# XMC4500 register map
Vendor: Infineon; File version: 1.2.0 (Reference Manual v1.2)
CPU: CM4 r2p0, little endian, MPU, FPU, 6 interrupt priority bits
Registers are 32-bit, read-write, reset 0x0 unless marked. A register's access mark holds for its fields unless they carry their own. Offsets are from the block's base; [hi:lo] are bit positions; {n}, {i} and the like mark numbered series.

## ETH0 — Ethernet Unit 0
Base 0x5000C000
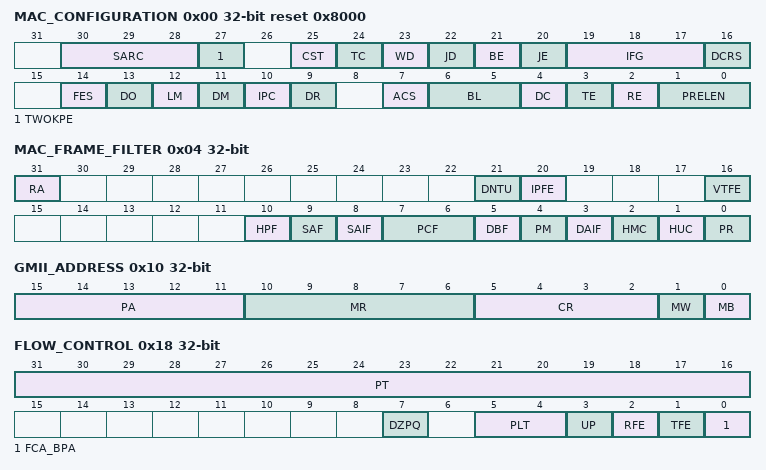
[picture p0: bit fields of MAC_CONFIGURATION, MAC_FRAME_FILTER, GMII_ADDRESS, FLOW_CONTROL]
0x00 MAC_CONFIGURATION access per field reset 0x8000
  [30:28] SARC ro — Source Address Insertion or Replacement Control
  [27] TWOKPE rw — IEEE 802.3as support for 2K packets Enable
  [25] CST rw — CRC Stripping of Type Frames
  [24] TC ro — Transmit Configuration in RMII
  [23] WD rw — Watchdog Disable
  [22] JD rw — Jabber Disable
  [21] BE ro — Frame Burst Enable
  [20] JE rw — Jumbo Frame Enable
  [19:17] IFG rw — Inter-Frame Gap
  [16] DCRS rw — Disable Carrier Sense During Transmission
  [14] FES rw — Speed
  [13] DO rw — Disable Receive Own
  [12] LM rw — Loopback Mode
  [11] DM rw — Duplex Mode
  [10] IPC rw — Checksum Offload
  [9] DR rw — Disable Retry
  [7] ACS rw — Automatic Pad or CRC Stripping
  [6:5] BL rw — Back-Off Limit
  [4] DC rw — Deferral Check
  [3] TE rw — Transmitter Enable
  [2] RE rw — Receiver Enable
  [1:0] PRELEN rw — Preamble Length for Transmit Frames
0x04 MAC_FRAME_FILTER access per field
  [31] RA rw — Receive All
  [21] DNTU ro — Drop non-TCP/UDP over IP Frames
  [20] IPFE ro — Layer 3 and Layer 4 Filter Enable
  [16] VTFE rw — VLAN Tag Filter Enable
  [10] HPF rw — Hash or Perfect Filter
  [9] SAF rw — Source Address Filter Enable
  [8] SAIF rw — SA Inverse Filtering
  [7:6] PCF rw — Pass Control Frames
  [5] DBF rw — Disable Broadcast Frames
  [4] PM rw — Pass All Multicast
  [3] DAIF rw — DA Inverse Filtering
  [2] HMC rw — Hash Multicast
  [1] HUC rw — Hash Unicast
  [0] PR rw — Promiscuous Mode
0x08 HASH_TABLE_HIGH
  [31:0] HTH — Hash Table High
0x0C HASH_TABLE_LOW
  [31:0] HTL — Hash Table Low
0x10 GMII_ADDRESS access per field — MII Address Register
  [15:11] PA rw — Physical Layer Address
  [10:6] MR rw — MII Register
  [5:2] CR rw — CSR Clock Range
  [1] MW rw — MII Write
  [0] MB rw — MII Busy
0x14 GMII_DATA access per field — MII Data Register
  [15:0] MD rw — MII Data
0x18 FLOW_CONTROL access per field
  [31:16] PT rw — Pause Time
  [7] DZPQ rw — Disable Zero-Quanta Pause
  [5:4] PLT rw — Pause Low Threshold
  [3] UP rw — Unicast Pause Frame Detect
  [2] RFE rw — Receive Flow Control Enable
  [1] TFE rw — Transmit Flow Control Enable
  [0] FCA_BPA rw — Flow Control Busy or Backpressure Activate
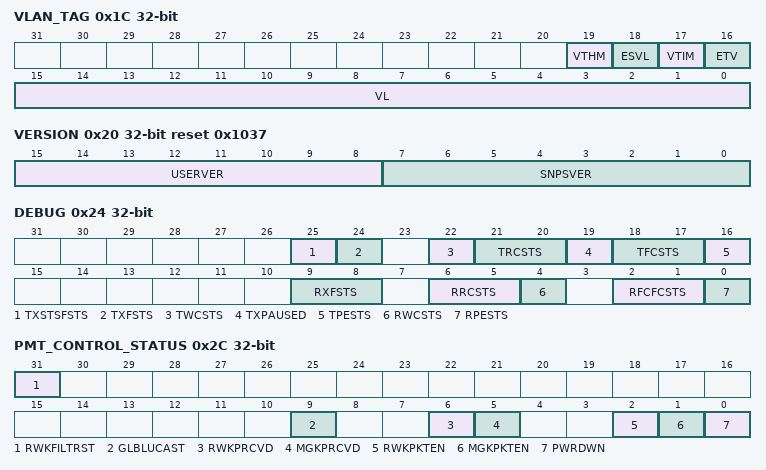
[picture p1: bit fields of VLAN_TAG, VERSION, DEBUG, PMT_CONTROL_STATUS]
0x1C VLAN_TAG access per field
  [19] VTHM ro — VLAN Tag Hash Table Match Enable
  [18] ESVL rw — Enable S-VLAN
  [17] VTIM rw — VLAN Tag Inverse Match Enable
  [16] ETV rw — Enable 12-Bit VLAN Tag Comparison
  [15:0] VL rw — VLAN Tag Identifier for Receive Frames
0x20 VERSION ro reset 0x1037
  [15:8] USERVER — User-defined Version (Configured with the coreConsultant)
  [7:0] SNPSVER — Synopsys-defined Version (3.7)
0x24 DEBUG ro
  [25] TXSTSFSTS — MTL TxStatus FIFO Full Status
  [24] TXFSTS — MTL Tx FIFO Not Empty Status
  [22] TWCSTS — MTL Tx FIFO Write Controller Active Status
  [21:20] TRCSTS — MTL Tx FIFO Read Controller Status
  [19] TXPAUSED — MAC transmitter in PAUSE
  [18:17] TFCSTS — MAC Transmit Frame Controller Status
  [16] TPESTS — MAC MII Transmit Protocol Engine Status
  [9:8] RXFSTS — MTL Rx FIFO Fill-level Status
  [6:5] RRCSTS — MTL Rx FIFO Read Controller State
  [4] RWCSTS — MTL Rx FIFO Write Controller Active Status
  [2:1] RFCFCSTS — MAC Receive Frame Controller FIFO Status
  [0] RPESTS — MAC MII Receive Protocol Engine Status
0x28 REMOTE_WAKE_UP_FRAME_FILTER
  [31:0] WKUPFRMFTR — Remote Wake-Up Frame Filter
0x2C PMT_CONTROL_STATUS access per field — PMT Control and Status Register
  [31] RWKFILTRST rw — Wake-Up Frame Filter Register Pointer Reset
  [9] GLBLUCAST rw — Global Unicast
  [6] RWKPRCVD ro — Wake-Up Frame Received
  [5] MGKPRCVD ro — Magic Packet Received
  [2] RWKPKTEN rw — Wake-Up Frame Enable
  [1] MGKPKTEN rw — Magic Packet Enable
  [0] PWRDWN rw — Power Down
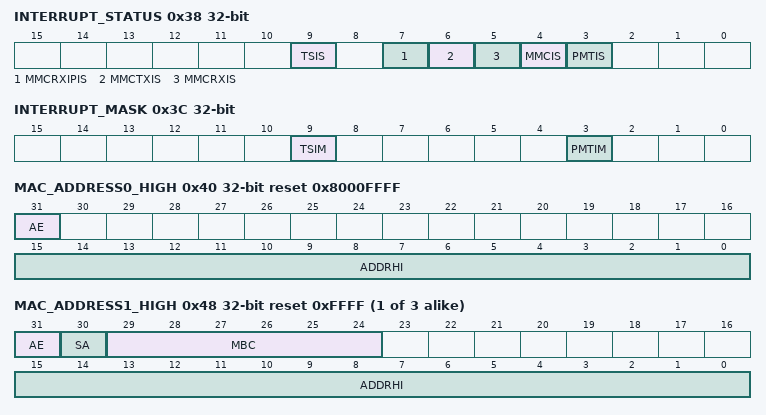
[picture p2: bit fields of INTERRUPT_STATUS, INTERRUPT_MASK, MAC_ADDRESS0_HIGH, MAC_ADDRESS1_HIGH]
0x38 INTERRUPT_STATUS ro — Interrupt Register
  [9] TSIS — Timestamp Interrupt Status
  [7] MMCRXIPIS — MMC Receive Checksum Offload Interrupt Status
  [6] MMCTXIS — MMC Transmit Interrupt Status
  [5] MMCRXIS — MMC Receive Interrupt Status
  [4] MMCIS — MMC Interrupt Status
  [3] PMTIS — PMT Interrupt Status
0x3C INTERRUPT_MASK access per field
  [9] TSIM rw — Timestamp Interrupt Mask
  [3] PMTIM rw — PMT Interrupt Mask
0x40 MAC_ADDRESS0_HIGH access per field reset 0x8000FFFF
  [31] AE ro — Address Enable
  [15:0] ADDRHI rw — MAC Address0 [47:32]
{0x44+8i} MAC_ADDRESS{i}_LOW reset 0xFFFFFFFF (i=0..3)
  [31:0] ADDRLO — MAC Address{i} [31:0]
{0x40+8i} MAC_ADDRESS{i}_HIGH access per field reset 0xFFFF (i=1..3)
  [31] AE rw — Address Enable
  [30] SA rw — Source Address
  [29:24] MBC rw — Mask Byte Control
  [15:0] ADDRHI rw — MAC Address{i} [47:32]
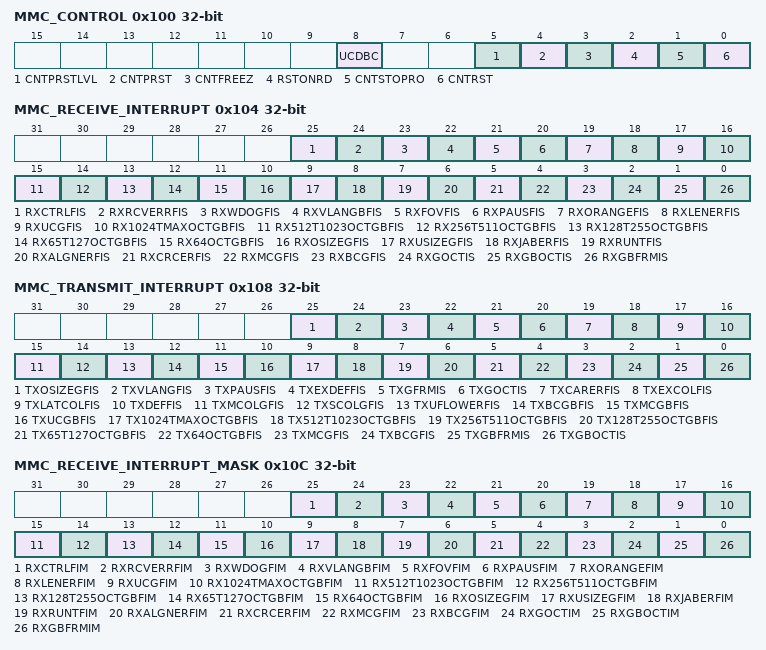
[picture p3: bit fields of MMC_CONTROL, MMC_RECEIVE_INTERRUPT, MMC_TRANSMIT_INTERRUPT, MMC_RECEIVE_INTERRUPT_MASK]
0x100 MMC_CONTROL access per field
  [8] UCDBC rw — Update MMC Counters for Dropped Broadcast Frames
  [5] CNTPRSTLVL rw — Full-Half Preset
  [4] CNTPRST rw — Counters Preset
  [3] CNTFREEZ rw — MMC Counter Freeze
  [2] RSTONRD rw — Reset on Read
  [1] CNTSTOPRO rw — Counters Stop Rollover
  [0] CNTRST rw — Counters Reset
0x104 MMC_RECEIVE_INTERRUPT ro
  [25] RXCTRLFIS — MMC Receive Control Frame Counter Interrupt Status
  [24] RXRCVERRFIS — MMC Receive Error Frame Counter Interrupt Status
  [23] RXWDOGFIS — MMC Receive Watchdog Error Frame Counter Interrupt Status
  [22] RXVLANGBFIS — MMC Receive VLAN Good Bad Frame Counter Interrupt Status
  [21] RXFOVFIS — MMC Receive FIFO Overflow Frame Counter Interrupt Status
  [20] RXPAUSFIS — MMC Receive Pause Frame Counter Interrupt Status
  [19] RXORANGEFIS — MMC Receive Out Of Range Error Frame Counter Interrupt Status
  [18] RXLENERFIS — MMC Receive Length Error Frame Counter Interrupt Status
  [17] RXUCGFIS — MMC Receive Unicast Good Frame Counter Interrupt Status
  [16] RX1024TMAXOCTGBFIS — MMC Receive 1024 to Maximum Octet Good Bad Frame Counter Interrupt Status
  [15] RX512T1023OCTGBFIS — MMC Receive 512 to 1023 Octet Good Bad Frame Counter Interrupt Status
  [14] RX256T511OCTGBFIS — MMC Receive 256 to 511 Octet Good Bad Frame Counter Interrupt Status
  [13] RX128T255OCTGBFIS — MMC Receive 128 to 255 Octet Good Bad Frame Counter Interrupt Status
  [12] RX65T127OCTGBFIS — MMC Receive 65 to 127 Octet Good Bad Frame Counter Interrupt Status
  [11] RX64OCTGBFIS — MMC Receive 64 Octet Good Bad Frame Counter Interrupt Status
  [10] RXOSIZEGFIS — MMC Receive Oversize Good Frame Counter Interrupt Status
  [9] RXUSIZEGFIS — MMC Receive Undersize Good Frame Counter Interrupt Status
  [8] RXJABERFIS — MMC Receive Jabber Error Frame Counter Interrupt Status
  [7] RXRUNTFIS — MMC Receive Runt Frame Counter Interrupt Status
  [6] RXALGNERFIS — MMC Receive Alignment Error Frame Counter Interrupt Status
  [5] RXCRCERFIS — MMC Receive CRC Error Frame Counter Interrupt Status
  [4] RXMCGFIS — MMC Receive Multicast Good Frame Counter Interrupt Status
  [3] RXBCGFIS — MMC Receive Broadcast Good Frame Counter Interrupt Status.
  [2] RXGOCTIS — MMC Receive Good Octet Counter Interrupt Status.
  [1] RXGBOCTIS — MMC Receive Good Bad Octet Counter Interrupt Status
  [0] RXGBFRMIS — MMC Receive Good Bad Frame Counter Interrupt Status
0x108 MMC_TRANSMIT_INTERRUPT ro
  [25] TXOSIZEGFIS — MMC Transmit Oversize Good Frame Counter Interrupt Status
  [24] TXVLANGFIS — MMC Transmit VLAN Good Frame Counter Interrupt Status
  [23] TXPAUSFIS — MMC Transmit Pause Frame Counter Interrupt Status
  [22] TXEXDEFFIS — MMC Transmit Excessive Deferral Frame Counter Interrupt Status
  [21] TXGFRMIS — MMC Transmit Good Frame Counter Interrupt Status
  [20] TXGOCTIS — MMC Transmit Good Octet Counter Interrupt Status
  [19] TXCARERFIS — MMC Transmit Carrier Error Frame Counter Interrupt Status
  [18] TXEXCOLFIS — MMC Transmit Excessive Collision Frame Counter Interrupt Status
  [17] TXLATCOLFIS — MMC Transmit Late Collision Frame Counter Interrupt Status
  [16] TXDEFFIS — MMC Transmit Deferred Frame Counter Interrupt Status
  [15] TXMCOLGFIS — MMC Transmit Multiple Collision Good Frame Counter Interrupt Status
  [14] TXSCOLGFIS — MMC Transmit Single Collision Good Frame Counter Interrupt Status
  [13] TXUFLOWERFIS — MMC Transmit Underflow Error Frame Counter Interrupt Status
  [12] TXBCGBFIS — MMC Transmit Broadcast Good Bad Frame Counter Interrupt Status
  [11] TXMCGBFIS — MMC Transmit Multicast Good Bad Frame Counter Interrupt Status
  [10] TXUCGBFIS — MMC Transmit Unicast Good Bad Frame Counter Interrupt Status
  [9] TX1024TMAXOCTGBFIS — MMC Transmit 1024 to Maximum Octet Good Bad Frame Counter Interrupt Status
  [8] TX512T1023OCTGBFIS — MMC Transmit 512 to 1023 Octet Good Bad Frame Counter Interrupt Status
  [7] TX256T511OCTGBFIS — MMC Transmit 256 to 511 Octet Good Bad Frame Counter Interrupt Status
  [6] TX128T255OCTGBFIS — MMC Transmit 128 to 255 Octet Good Bad Frame Counter Interrupt Status
  [5] TX65T127OCTGBFIS — MMC Transmit 65 to 127 Octet Good Bad Frame Counter Interrupt Status
  [4] TX64OCTGBFIS — MMC Transmit 64 Octet Good Bad Frame Counter Interrupt Status.
  [3] TXMCGFIS — MMC Transmit Multicast Good Frame Counter Interrupt Status
  [2] TXBCGFIS — MMC Transmit Broadcast Good Frame Counter Interrupt Status
  [1] TXGBFRMIS — MMC Transmit Good Bad Frame Counter Interrupt Status
  [0] TXGBOCTIS — MMC Transmit Good Bad Octet Counter Interrupt Status
0x10C MMC_RECEIVE_INTERRUPT_MASK access per field — MMC Reveive Interrupt Mask Register
  [25] RXCTRLFIM rw — MMC Receive Control Frame Counter Interrupt Mask
  [24] RXRCVERRFIM rw — MMC Receive Error Frame Counter Interrupt Mask
  [23] RXWDOGFIM rw — MMC Receive Watchdog Error Frame Counter Interrupt Mask
  [22] RXVLANGBFIM rw — MMC Receive VLAN Good Bad Frame Counter Interrupt Mask
  [21] RXFOVFIM rw — MMC Receive FIFO Overflow Frame Counter Interrupt Mask
  [20] RXPAUSFIM rw — MMC Receive Pause Frame Counter Interrupt Mask
  [19] RXORANGEFIM rw — MMC Receive Out Of Range Error Frame Counter Interrupt Mask
  [18] RXLENERFIM rw — MMC Receive Length Error Frame Counter Interrupt Mask
  [17] RXUCGFIM rw — MMC Receive Unicast Good Frame Counter Interrupt Mask
  [16] RX1024TMAXOCTGBFIM rw — MMC Receive 1024 to Maximum Octet Good Bad Frame Counter Interrupt Mask
  [15] RX512T1023OCTGBFIM rw — MMC Receive 512 to 1023 Octet Good Bad Frame Counter Interrupt Mask
  [14] RX256T511OCTGBFIM rw — MMC Receive 256 to 511 Octet Good Bad Frame Counter Interrupt Mask
  [13] RX128T255OCTGBFIM rw — MMC Receive 128 to 255 Octet Good Bad Frame Counter Interrupt Mask
  [12] RX65T127OCTGBFIM rw — MMC Receive 65 to 127 Octet Good Bad Frame Counter Interrupt Mask
  [11] RX64OCTGBFIM rw — MMC Receive 64 Octet Good Bad Frame Counter Interrupt Mask
  [10] RXOSIZEGFIM rw — MMC Receive Oversize Good Frame Counter Interrupt Mask
  [9] RXUSIZEGFIM rw — MMC Receive Undersize Good Frame Counter Interrupt Mask
  [8] RXJABERFIM rw — MMC Receive Jabber Error Frame Counter Interrupt Mask
  [7] RXRUNTFIM rw — MMC Receive Runt Frame Counter Interrupt Mask
  [6] RXALGNERFIM rw — MMC Receive Alignment Error Frame Counter Interrupt Mask
  [5] RXCRCERFIM rw — MMC Receive CRC Error Frame Counter Interrupt Mask
  [4] RXMCGFIM rw — MMC Receive Multicast Good Frame Counter Interrupt Mask
  [3] RXBCGFIM rw — MMC Receive Broadcast Good Frame Counter Interrupt Mask
  [2] RXGOCTIM rw — MMC Receive Good Octet Counter Interrupt Mask
  [1] RXGBOCTIM rw — MMC Receive Good Bad Octet Counter Interrupt Mask
  [0] RXGBFRMIM rw — MMC Receive Good Bad Frame Counter Interrupt Mask
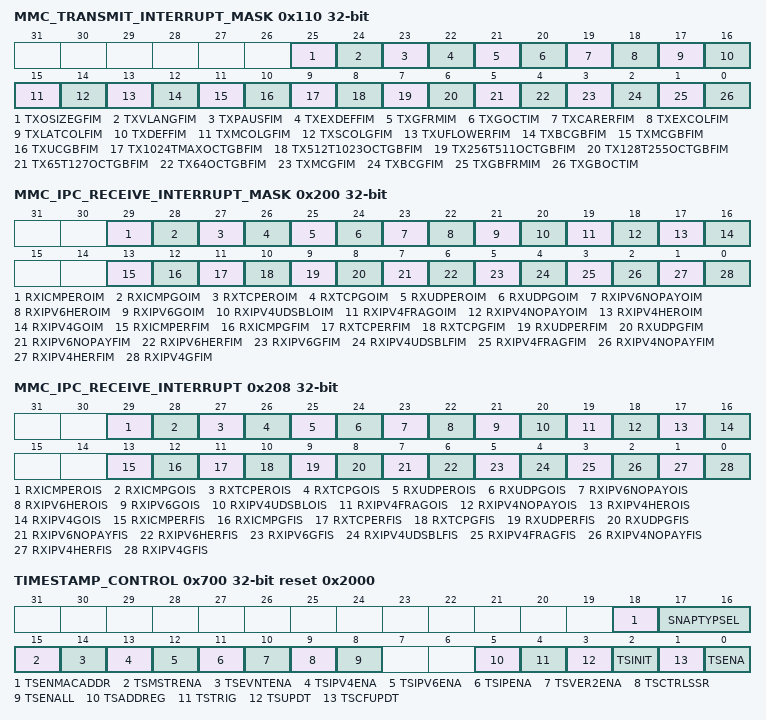
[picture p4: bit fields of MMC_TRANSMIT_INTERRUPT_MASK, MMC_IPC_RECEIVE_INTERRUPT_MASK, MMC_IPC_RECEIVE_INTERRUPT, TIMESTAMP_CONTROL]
0x110 MMC_TRANSMIT_INTERRUPT_MASK access per field
  [25] TXOSIZEGFIM rw — MMC Transmit Oversize Good Frame Counter Interrupt Mask
  [24] TXVLANGFIM rw — MMC Transmit VLAN Good Frame Counter Interrupt Mask
  [23] TXPAUSFIM rw — MMC Transmit Pause Frame Counter Interrupt Mask
  [22] TXEXDEFFIM rw — MMC Transmit Excessive Deferral Frame Counter Interrupt Mask
  [21] TXGFRMIM rw — MMC Transmit Good Frame Counter Interrupt Mask
  [20] TXGOCTIM rw — MMC Transmit Good Octet Counter Interrupt Mask
  [19] TXCARERFIM rw — MMC Transmit Carrier Error Frame Counter Interrupt Mask
  [18] TXEXCOLFIM rw — MMC Transmit Excessive Collision Frame Counter Interrupt Mask
  [17] TXLATCOLFIM rw — MMC Transmit Late Collision Frame Counter Interrupt Mask
  [16] TXDEFFIM rw — MMC Transmit Deferred Frame Counter Interrupt Mask
  [15] TXMCOLGFIM rw — MMC Transmit Multiple Collision Good Frame Counter Interrupt Mask
  [14] TXSCOLGFIM rw — MMC Transmit Single Collision Good Frame Counter Interrupt Mask
  [13] TXUFLOWERFIM rw — MMC Transmit Underflow Error Frame Counter Interrupt Mask
  [12] TXBCGBFIM rw — MMC Transmit Broadcast Good Bad Frame Counter Interrupt Mask
  [11] TXMCGBFIM rw — MMC Transmit Multicast Good Bad Frame Counter Interrupt Mask
  [10] TXUCGBFIM rw — MMC Transmit Unicast Good Bad Frame Counter Interrupt Mask
  [9] TX1024TMAXOCTGBFIM rw — MMC Transmit 1024 to Maximum Octet Good Bad Frame Counter Interrupt Mask
  [8] TX512T1023OCTGBFIM rw — MMC Transmit 512 to 1023 Octet Good Bad Frame Counter Interrupt Mask
  [7] TX256T511OCTGBFIM rw — MMC Transmit 256 to 511 Octet Good Bad Frame Counter Interrupt Mask
  [6] TX128T255OCTGBFIM rw — MMC Transmit 128 to 255 Octet Good Bad Frame Counter Interrupt Mask
  [5] TX65T127OCTGBFIM rw — MMC Transmit 65 to 127 Octet Good Bad Frame Counter Interrupt Mask
  [4] TX64OCTGBFIM rw — MMC Transmit 64 Octet Good Bad Frame Counter Interrupt Mask
  [3] TXMCGFIM rw — MMC Transmit Multicast Good Frame Counter Interrupt Mask
  [2] TXBCGFIM rw — MMC Transmit Broadcast Good Frame Counter Interrupt Mask
  [1] TXGBFRMIM rw — MMC Transmit Good Bad Frame Counter Interrupt Mask
  [0] TXGBOCTIM rw — MMC Transmit Good Bad Octet Counter Interrupt Mask
0x114 TX_OCTET_COUNT_GOOD_BAD ro — Transmit Octet Count for Good and Bad Frames Register
  [31:0] TXOCTGB — This field indicates the number of bytes transmitted in good and bad frames exclusive of preamble and retried bytes.
0x118 TX_FRAME_COUNT_GOOD_BAD ro — Transmit Frame Count for Goodand Bad Frames Register
  [31:0] TXFRMGB — This field indicates the number of good and bad frames transmitted, exclusive of retried frames
0x11C TX_BROADCAST_FRAMES_GOOD ro — Transmit Frame Count for Good Broadcast Frames
  [31:0] TXBCASTG — This field indicates the number of transmitted good broadcast frames.
0x120 TX_MULTICAST_FRAMES_GOOD ro — Transmit Frame Count for Good Multicast Frames
  [31:0] TXMCASTG — This field indicates the number of transmitted good multicast frames.
0x124 TX_64OCTETS_FRAMES_GOOD_BAD ro — Transmit Octet Count for Good and Bad 64 Byte Frames
  [31:0] TX64OCTGB — This field indicates the number of transmitted good and bad frames with length of 64 bytes, exclusive of preamble and retried frames.
0x128 TX_65TO127OCTETS_FRAMES_GOOD_BAD ro — Transmit Octet Count for Good and Bad 65 to 127 Bytes Frames
  [31:0] TX65_127OCTGB — This field indicates the number of transmitted good and bad frames with length between 65 and 127 (inclusive) bytes, exclusive of preamble and retried frames.
0x12C TX_128TO255OCTETS_FRAMES_GOOD_BAD ro — Transmit Octet Count for Good and Bad 128 to 255 Bytes Frames
  [31:0] TX128_255OCTGB — This field indicates the number of transmitted good and bad frames with length between 128 and 255 (inclusive) bytes, exclusive of preamble and retried frames.
0x130 TX_256TO511OCTETS_FRAMES_GOOD_BAD ro — Transmit Octet Count for Good and Bad 256 to 511 Bytes Frames
  [31:0] TX256_511OCTGB — This field indicates the number of transmitted good and bad frames with length between 256 and 511 (inclusive) bytes, exclusive of preamble and retried frames.
0x134 TX_512TO1023OCTETS_FRAMES_GOOD_BAD ro — Transmit Octet Count for Good and Bad 512 to 1023 Bytes Frames
  [31:0] TX512_1023OCTGB — This field indicates the number of transmitted good and bad frames with length between 512 and 1,023 (inclusive) bytes, exclusive of preamble and retried frames.
0x138 TX_1024TOMAXOCTETS_FRAMES_GOOD_BAD ro — Transmit Octet Count for Good and Bad 1024 to Maxsize Bytes Frames
  [31:0] TX1024_MAXOCTGB — This field indicates the number of good and bad frames transmitted with length between 1,024 and maxsize (inclusive) bytes, exclusive of preamble and retried frames.
0x13C TX_UNICAST_FRAMES_GOOD_BAD ro — Transmit Frame Count for Good and Bad Unicast Frames
  [31:0] TXUCASTGB — This field indicates the number of transmitted good and bad unicast frames.
0x140 TX_MULTICAST_FRAMES_GOOD_BAD ro — Transmit Frame Count for Good and Bad Multicast Frames
  [31:0] TXMCASTGB — This field indicates the number of transmitted good and bad multicast frames.
0x144 TX_BROADCAST_FRAMES_GOOD_BAD ro — Transmit Frame Count for Good and Bad Broadcast Frames
  [31:0] TXBCASTGB — This field indicates the number of transmitted good and bad broadcast frames.
0x148 TX_UNDERFLOW_ERROR_FRAMES ro — Transmit Frame Count for Underflow Error Frames
  [31:0] TXUNDRFLW — This field indicates the number of frames aborted because of frame underflow error.
0x14C TX_SINGLE_COLLISION_GOOD_FRAMES ro — Transmit Frame Count for Frames Transmitted after Single Collision
  [31:0] TXSNGLCOLG — This field indicates the number of successfully transmitted frames after a single collision in the half-duplex mode.
0x150 TX_MULTIPLE_COLLISION_GOOD_FRAMES ro — Transmit Frame Count for Frames Transmitted after Multiple Collision
  [31:0] TXMULTCOLG — This field indicates the number of successfully transmitted frames after multiple collisions in the half-duplex mode.
0x154 TX_DEFERRED_FRAMES ro
  [31:0] TXDEFRD — This field indicates the number of successfully transmitted frames after a deferral in the half-duplex mode.
0x158 TX_LATE_COLLISION_FRAMES ro — Transmit Frame Count for Late Collision Error Frames
  [31:0] TXLATECOL — This field indicates the number of frames aborted because of late collision error.
0x15C TX_EXCESSIVE_COLLISION_FRAMES ro — Transmit Frame Count for Excessive Collision Error Frames
  [31:0] TXEXSCOL — This field indicates the number of frames aborted because of excessive (16) collision error.
0x160 TX_CARRIER_ERROR_FRAMES ro — Transmit Frame Count for Carrier Sense Error Frames
  [31:0] TXCARR — This field indicates the number of frames aborted because of carrier sense error (no carrier or loss of carrier).
0x164 TX_OCTET_COUNT_GOOD ro
  [31:0] TXOCTG — This field indicates the number of bytes transmitted, exclusive of preamble, in good frames.
0x168 TX_FRAME_COUNT_GOOD ro
  [31:0] TXFRMG — This field indicates the number of transmitted good frames, exclusive of preamble.
0x16C TX_EXCESSIVE_DEFERRAL_ERROR ro — Transmit Frame Count for Excessive Deferral Error Frames
  [31:0] TXEXSDEF — This field indicates the number of frames aborted because of excessive deferral error, that is, frames deferred for more than two max-sized frame times.
0x170 TX_PAUSE_FRAMES ro — Transmit Frame Count for Good PAUSE Frames
  [31:0] TXPAUSE — This field indicates the number of transmitted good PAUSE frames.
0x174 TX_VLAN_FRAMES_GOOD ro — Transmit Frame Count for Good VLAN Frames
  [31:0] TXVLANG — This register maintains the number of transmitted good VLAN frames, exclusive of retried frames.
0x178 TX_OSIZE_FRAMES_GOOD ro — Transmit Frame Count for Good Oversize Frames
  [31:0] TXOSIZG — This field indicates the number of frames transmitted without errors and with length greater than the maxsize (1,518 or 1,522 bytes for VLAN tagged frames; 2000 bytes if enabled by setting MAC Configuration.2KPE).
0x180 RX_FRAMES_COUNT_GOOD_BAD ro — Receive Frame Count for Good and Bad Frames
  [31:0] RXFRMGB — This field indicates the number of received good and bad frames.
0x184 RX_OCTET_COUNT_GOOD_BAD ro — Receive Octet Count for Good and Bad Frames
  [31:0] RXOCTGB — This field indicates the number of bytes received, exclusive of preamble, in good and bad frames.
0x188 RX_OCTET_COUNT_GOOD ro
  [31:0] RXOCTG — This field indicates the number of bytes received, exclusive of preamble, only in good frames.
0x18C RX_BROADCAST_FRAMES_GOOD ro — Receive Frame Count for Good Broadcast Frames
  [31:0] RXBCASTG — This field indicates the number of received good broadcast frames.
0x190 RX_MULTICAST_FRAMES_GOOD ro — Receive Frame Count for Good Multicast Frames
  [31:0] RXMCASTG — This field indicates the number of received good multicast frames.
0x194 RX_CRC_ERROR_FRAMES ro — Receive Frame Count for CRC Error Frames
  [31:0] RXCRCERR — This field indicates the number of frames received with CRC error.
0x198 RX_ALIGNMENT_ERROR_FRAMES ro — Receive Frame Count for Alignment Error Frames
  [31:0] RXALGNERR — This field indicates the number of frames received with alignment (dribble) error.
0x19C RX_RUNT_ERROR_FRAMES ro — Receive Frame Count for Runt Error Frames
  [31:0] RXRUNTERR — This field indicates the number of frames received with runt error(<64 bytes and CRC error).
0x1A0 RX_JABBER_ERROR_FRAMES ro — Receive Frame Count for Jabber Error Frames
  [31:0] RXJABERR — This field indicates the number of giant frames received with length (including CRC) greater than 1,518 bytes (1,522 bytes for VLAN tagged) and with CRC error. If Jumbo Frame mode is enabled, then frames of length greater than 9,018 bytes (9,022 for VLAN tagged) are considered as giant frames.
0x1A4 RX_UNDERSIZE_FRAMES_GOOD ro — Receive Frame Count for Undersize Frames
  [31:0] RXUNDERSZG — This field indicates the number of frames received with length less than 64 bytes and without errors.
0x1A8 RX_OVERSIZE_FRAMES_GOOD ro
  [31:0] RXOVERSZG — This field indicates the number of frames received without errors, with length greater than the maxsize (1,518 or 1,522 for VLAN tagged frames; 2,000 bytes if enabled by setting MAC Configuration.2KPE).
0x1AC RX_64OCTETS_FRAMES_GOOD_BAD ro — Receive Frame Count for Good and Bad 64 Byte Frames
  [31:0] RX64OCTGB — This field indicates the number of received good and bad frames with length 64 bytes, exclusive of preamble.
0x1B0 RX_65TO127OCTETS_FRAMES_GOOD_BAD ro — Receive Frame Count for Good and Bad 65 to 127 Bytes Frames
  [31:0] RX65_127OCTGB — This field indicates the number of received good and bad frames received with length between 65 and 127 (inclusive) bytes, exclusive of preamble.
0x1B4 RX_128TO255OCTETS_FRAMES_GOOD_BAD ro — Receive Frame Count for Good and Bad 128 to 255 Bytes Frames
  [31:0] RX128_255OCTGB — This field indicates the number of received good and bad frames with length between 128 and 255 (inclusive) bytes, exclusive of preamble.
0x1B8 RX_256TO511OCTETS_FRAMES_GOOD_BAD ro — Receive Frame Count for Good and Bad 256 to 511 Bytes Frames
  [31:0] RX256_511OCTGB — This field indicates the number of received good and bad frames with length between 256 and 511 (inclusive) bytes, exclusive of preamble.
0x1BC RX_512TO1023OCTETS_FRAMES_GOOD_BAD ro — Receive Frame Count for Good and Bad 512 to 1,023 Bytes Frames
  [31:0] RX512_1023OCTGB — This field indicates the number of received good and bad frames with length between 512 and 1,023 (inclusive) bytes, exclusive of preamble.
0x1C0 RX_1024TOMAXOCTETS_FRAMES_GOOD_BAD ro — Receive Frame Count for Good and Bad 1,024 to Maxsize Bytes Frames
  [31:0] RX1024_MAXOCTGB — This field indicates the number of received good and bad frames with length between 1,024 and maxsize (inclusive) bytes, exclusive of preamble and retried frames.
0x1C4 RX_UNICAST_FRAMES_GOOD ro — Receive Frame Count for Good Unicast Frames
  [31:0] RXUCASTG — This field indicates the number of received good unicast frames.
0x1C8 RX_LENGTH_ERROR_FRAMES ro — Receive Frame Count for Length Error Frames
  [31:0] RXLENERR — This field indicates the number of frames received with length error (Length type field not equal to frame size) for all frames with valid length field.
0x1CC RX_OUT_OF_RANGE_TYPE_FRAMES ro — Receive Frame Count for Out of Range Frames
  [31:0] RXOUTOFRNG — This field indicates the number of received frames with length field not equal to the valid frame size (greater than 1,500 but less than 1,536).
0x1D0 RX_PAUSE_FRAMES ro — Receive Frame Count for PAUSE Frames
  [31:0] RXPAUSEFRM — This field indicates the number of received good and valid PAUSE frames.
0x1D4 RX_FIFO_OVERFLOW_FRAMES ro — Receive Frame Count for FIFO Overflow Frames
  [31:0] RXFIFOOVFL — This field indicates the number of received frames missed because of FIFO overflow.
0x1D8 RX_VLAN_FRAMES_GOOD_BAD ro — Receive Frame Count for Good and Bad VLAN Frames
  [31:0] RXVLANFRGB — This field indicates the number of received good and bad VLAN frames.
0x1DC RX_WATCHDOG_ERROR_FRAMES ro — Receive Frame Count for Watchdog Error Frames
  [31:0] RXWDGERR — This field indicates the number of frames received with error because of the watchdog timeout error (frames with more than 2,048 bytes data load).
0x1E0 RX_RECEIVE_ERROR_FRAMES ro — Receive Frame Count for Receive Error Frames
  [31:0] RXRCVERR — This field indicates the number of frames received with error because of the watchdog timeout error (frames with more than 2,048 bytes data load).
0x1E4 RX_CONTROL_FRAMES_GOOD ro — Receive Frame Count for Good Control Frames Frames
  [31:0] RXCTRLG — This field indicates the number of frames received with error because of the watchdog timeout error (frames with more than 2,048 bytes data load).
0x200 MMC_IPC_RECEIVE_INTERRUPT_MASK access per field — MMC Receive Checksum Offload Interrupt Mask Register
  [29] RXICMPEROIM rw — MMC Receive ICMP Error Octet Counter Interrupt Mask
  [28] RXICMPGOIM rw — MMC Receive ICMP Good Octet Counter Interrupt Mask
  [27] RXTCPEROIM rw — MMC Receive TCP Error Octet Counter Interrupt Mask
  [26] RXTCPGOIM rw — MMC Receive TCP Good Octet Counter Interrupt Mask
  [25] RXUDPEROIM rw — MMC Receive UDP Error Octet Counter Interrupt Mask
  [24] RXUDPGOIM rw — MMC Receive UDP Good Octet Counter Interrupt Mask
  [23] RXIPV6NOPAYOIM rw — MMC Receive IPV6 No Payload Octet Counter Interrupt Mask
  [22] RXIPV6HEROIM rw — MMC Receive IPV6 Header Error Octet Counter Interrupt Mask
  [21] RXIPV6GOIM rw — MMC Receive IPV6 Good Octet Counter Interrupt Mask
  [20] RXIPV4UDSBLOIM rw — MMC Receive IPV4 UDP Checksum Disabled Octet Counter Interrupt Mask
  [19] RXIPV4FRAGOIM rw — MMC Receive IPV4 Fragmented Octet Counter Interrupt Mask
  [18] RXIPV4NOPAYOIM rw — MMC Receive IPV4 No Payload Octet Counter Interrupt Mask
  [17] RXIPV4HEROIM rw — MMC Receive IPV4 Header Error Octet Counter Interrupt Mask
  [16] RXIPV4GOIM rw — MMC Receive IPV4 Good Octet Counter Interrupt Mask
  [13] RXICMPERFIM rw — MMC Receive ICMP Error Frame Counter Interrupt Mask
  [12] RXICMPGFIM rw — MMC Receive ICMP Good Frame Counter Interrupt Mask
  [11] RXTCPERFIM rw — MMC Receive TCP Error Frame Counter Interrupt Mask
  [10] RXTCPGFIM rw — MMC Receive TCP Good Frame Counter Interrupt Mask
  [9] RXUDPERFIM rw — MMC Receive UDP Error Frame Counter Interrupt Mask
  [8] RXUDPGFIM rw — MMC Receive UDP Good Frame Counter Interrupt Mask
  [7] RXIPV6NOPAYFIM rw — MMC Receive IPV6 No Payload Frame Counter Interrupt Mask
  [6] RXIPV6HERFIM rw — MMC Receive IPV6 Header Error Frame Counter Interrupt Mask
  [5] RXIPV6GFIM rw — MMC Receive IPV6 Good Frame Counter Interrupt Mask
  [4] RXIPV4UDSBLFIM rw — MMC Receive IPV4 UDP Checksum Disabled Frame Counter Interrupt Mask
  [3] RXIPV4FRAGFIM rw — MMC Receive IPV4 Fragmented Frame Counter Interrupt Mask
  [2] RXIPV4NOPAYFIM rw — MMC Receive IPV4 No Payload Frame Counter Interrupt Mask
  [1] RXIPV4HERFIM rw — MMC Receive IPV4 Header Error Frame Counter Interrupt Mask
  [0] RXIPV4GFIM rw — MMC Receive IPV4 Good Frame Counter Interrupt Mask
0x208 MMC_IPC_RECEIVE_INTERRUPT ro — MMC Receive Checksum Offload Interrupt Register
  [29] RXICMPEROIS — MMC Receive ICMP Error Octet Counter Interrupt Status
  [28] RXICMPGOIS — MMC Receive ICMP Good Octet Counter Interrupt Status
  [27] RXTCPEROIS — MMC Receive TCP Error Octet Counter Interrupt Status
  [26] RXTCPGOIS — MMC Receive TCP Good Octet Counter Interrupt Status
  [25] RXUDPEROIS — MMC Receive UDP Error Octet Counter Interrupt Status
  [24] RXUDPGOIS — MMC Receive UDP Good Octet Counter Interrupt Status
  [23] RXIPV6NOPAYOIS — MMC Receive IPV6 No Payload Octet Counter Interrupt Status
  [22] RXIPV6HEROIS — MMC Receive IPV6 Header Error Octet Counter Interrupt Status
  [21] RXIPV6GOIS — MMC Receive IPV6 Good Octet Counter Interrupt Status
  [20] RXIPV4UDSBLOIS — MMC Receive IPV4 UDP Checksum Disabled Octet Counter Interrupt Status
  [19] RXIPV4FRAGOIS — MMC Receive IPV4 Fragmented Octet Counter Interrupt Status
  [18] RXIPV4NOPAYOIS — MMC Receive IPV4 No Payload Octet Counter Interrupt Status
  [17] RXIPV4HEROIS — MMC Receive IPV4 Header Error Octet Counter Interrupt Status
  [16] RXIPV4GOIS — MMC Receive IPV4 Good Octet Counter Interrupt Status
  [13] RXICMPERFIS — MMC Receive ICMP Error Frame Counter Interrupt Status
  [12] RXICMPGFIS — MMC Receive ICMP Good Frame Counter Interrupt Status
  [11] RXTCPERFIS — MMC Receive TCP Error Frame Counter Interrupt Status
  [10] RXTCPGFIS — MMC Receive TCP Good Frame Counter Interrupt Status
  [9] RXUDPERFIS — MMC Receive UDP Error Frame Counter Interrupt Status
  [8] RXUDPGFIS — MMC Receive UDP Good Frame Counter Interrupt Status
  [7] RXIPV6NOPAYFIS — MMC Receive IPV6 No Payload Frame Counter Interrupt Status
  [6] RXIPV6HERFIS — MMC Receive IPV6 Header Error Frame Counter Interrupt Status
  [5] RXIPV6GFIS — MMC Receive IPV6 Good Frame Counter Interrupt Status
  [4] RXIPV4UDSBLFIS — MMC Receive IPV4 UDP Checksum Disabled Frame Counter Interrupt Status
  [3] RXIPV4FRAGFIS — MMC Receive IPV4 Fragmented Frame Counter Interrupt Status
  [2] RXIPV4NOPAYFIS — MMC Receive IPV4 No Payload Frame Counter Interrupt Status
  [1] RXIPV4HERFIS — MMC Receive IPV4 Header Error Frame Counter Interrupt Status
  [0] RXIPV4GFIS — MMC Receive IPV4 Good Frame Counter Interrupt Status
0x210 RXIPV4_GOOD_FRAMES ro
  [31:0] RXIPV4GDFRM — This field indicates the number of good IPv4 datagrams received with the TCP, UDP, or ICMP payload.
0x214 RXIPV4_HEADER_ERROR_FRAMES ro — Receive IPV4 Header Error Frame Counter Register
  [31:0] RXIPV4HDRERRFRM — This field indicates the number of IPv4 datagrams received with header errors (checksum, length, or version mismatch).
0x218 RXIPV4_NO_PAYLOAD_FRAMES ro — Receive IPV4 No Payload Frame Counter Register
  [31:0] RXIPV4NOPAYFRM — This field indicates the number of IPv4 datagram frames received that did not have a TCP, UDP, or ICMP payload processed by the Checksum engine.
0x21C RXIPV4_FRAGMENTED_FRAMES ro — Receive IPV4 Fragmented Frame Counter Register
  [31:0] RXIPV4FRAGFRM — This field indicates the number of good IPv4 datagrams received with fragmentation.
0x220 RXIPV4_UDP_CHECKSUM_DISABLED_FRAMES ro — Receive IPV4 UDP Checksum Disabled Frame Counter Register
  [31:0] RXIPV4UDSBLFRM — This field indicates the number of received good IPv4 datagrams which have the UDP payload with checksum disabled.
0x224 RXIPV6_GOOD_FRAMES ro
  [31:0] RXIPV6GDFRM — This field indicates the number of good IPv6 datagrams received with TCP, UDP, or ICMP payloads.
0x228 RXIPV6_HEADER_ERROR_FRAMES ro — Receive IPV6 Header Error Frame Counter Register
  [31:0] RXIPV6HDRERRFRM — This field indicates the number of IPv6 datagrams received with header errors (length or version mismatch).
0x22C RXIPV6_NO_PAYLOAD_FRAMES ro — Receive IPV6 No Payload Frame Counter Register
  [31:0] RXIPV6NOPAYFRM — This field indicates the number of IPv6 datagram frames received that did not have a TCP, UDP, or ICMP payload. This includes all IPv6 datagrams with fragmentation or security extension headers.
0x230 RXUDP_GOOD_FRAMES ro
  [31:0] RXUDPGDFRM — This field indicates the number of good IP datagrams with a good UDP payload. This counter is not updated when the counter is incremented.
0x234 RXUDP_ERROR_FRAMES ro
  [31:0] RXUDPERRFRM — This field indicates the number of good IP datagrams whose UDP payload has a checksum error.
0x238 RXTCP_GOOD_FRAMES ro
  [31:0] RXTCPGDFRM — This field indicates the number of good IP datagrams with a good TCP payload.
0x23C RXTCP_ERROR_FRAMES ro
  [31:0] RXTCPERRFRM — This field indicates the number of good IP datagrams whose TCP payload has a checksum error.
0x240 RXICMP_GOOD_FRAMES ro
  [31:0] RXICMPGDFRM — This field indicates the number of good IP datagrams with a good ICMP payload.
0x244 RXICMP_ERROR_FRAMES ro
  [31:0] RXICMPERRFRM — This field indicates the number of good IP datagrams whose ICMP payload has a checksum error.
0x250 RXIPV4_GOOD_OCTETS ro
  [31:0] RXIPV4GDOCT — This field indicates the number of bytes received in good IPv4 datagrams encapsulating TCP, UDP, or ICMP data. The Ethernet header, FCS, pad, or IP pad
0x254 RXIPV4_HEADER_ERROR_OCTETS ro — Receive IPV4 Header Error Octet Counter Register
  [31:0] RXIPV4HDRERROCT — This field indicates the number of bytes received in the IPv4 datagrams with header errors (checksum, length, or version mismatch). The value in the Length field of IPv4 header is used to update this counter.
0x258 RXIPV4_NO_PAYLOAD_OCTETS ro — Receive IPV4 No Payload Octet Counter Register
  [31:0] RXIPV4NOPAYOCT — This field indicates the number of bytes received in IPv4 datagrams that did not have a TCP, UDP, or ICMP payload. The value in the IPv4 headers Length field is used to update this counter.
0x25C RXIPV4_FRAGMENTED_OCTETS ro — Receive IPV4 Fragmented Octet Counter Register
  [31:0] RXIPV4FRAGOCT — This field indicates the number of bytes received in fragmented IPv4 datagrams. The value in the IPv4 headers Length field is used to update this counter.
0x260 RXIPV4_UDP_CHECKSUM_DISABLE_OCTETS ro — Receive IPV4 Fragmented Octet Counter Register
  [31:0] RXIPV4UDSBLOCT — This field indicates the number of bytes received in a UDP segment that had the UDP checksum disabled. This counter does not count the IP Header bytes. The Ethernet header, FCS, pad, or IP pad bytes are not included in this counter.
0x264 RXIPV6_GOOD_OCTETS ro
  [31:0] RXIPV6GDOCT — Thsi field indicates the number of bytes received in good IPv6 datagrams encapsulating TCP, UDP or ICMPv6 data.
0x268 RXIPV6_HEADER_ERROR_OCTETS ro — Receive IPV6 Header Error Octet Counter Register
  [31:0] RXIPV6HDRERROCT — This field indicates the number of bytes received in IPv6 datagrams with header errors (length or version mismatch). The value in the IPv6 headers Length field is used to update this counter.
0x26C RXIPV6_NO_PAYLOAD_OCTETS ro — Receive IPV6 No Payload Octet Counter Register
  [31:0] RXIPV6NOPAYOCT — This field indicates the number of bytes received in IPv6 datagrams that did not have a TCP, UDP, or ICMP payload. The value in the IPv6 headers Length field is used to update this counter.
0x270 RXUDP_GOOD_OCTETS ro — Receive UDP Good Octets Register
  [31:0] RXUDPGDOCT — This field indicates the number of bytes received in a good UDP segment. This counter does not count IP header bytes. The Ethernet header, FCS, pad, or IP pad bytes are not included in this counter.
0x274 RXUDP_ERROR_OCTETS ro — Receive UDP Error Octets Register
  [31:0] RXUDPERROCT — This field indicates the number of bytes received in a UDP segment with checksum errors. This counter does not count the IP Header bytes. The Ethernet header, FCS, pad, or IP pad bytes are not included in this counter.
0x278 RXTCP_GOOD_OCTETS ro — Receive TCP Good Octets Register
  [31:0] RXTCPGDOCT — This field indicates the number of bytes received in a good TCP segment. This counter does not count the IP Header bytes. The Ethernet header, FCS, pad, or IP pad bytes are not included in this counter.
0x27C RXTCP_ERROR_OCTETS ro — Receive TCP Error Octets Register
  [31:0] RXTCPERROCT — Thsi field indicates the number of bytes received in a TCP segment with checksum errors. This counter does not count the IP Header bytes. The Ethernet header, FCS, pad, or IP pad bytes are not included in this counter.
0x280 RXICMP_GOOD_OCTETS ro — Receive ICMP Good Octets Register
  [31:0] RXICMPGDOCT — This field indicates the number of bytes received in a good ICMP segment. This counter does not count the IP Header bytes. The Ethernet header, FCS, pad, or IP pad bytes are not included in this counter.
0x284 RXICMP_ERROR_OCTETS ro — Receive ICMP Error Octets Register
  [31:0] RXICMPERROCT — Number of bytes received in an ICMP segment with checksum errors
0x700 TIMESTAMP_CONTROL access per field reset 0x2000
  [18] TSENMACADDR rw — Enable MAC address for PTP Frame Filtering
  [17:16] SNAPTYPSEL rw — Select PTP packets for Taking Snapshots
  [15] TSMSTRENA rw — Enable Snapshot for Messages Relevant to Master
  [14] TSEVNTENA rw — Enable Timestamp Snapshot for Event Messages
  [13] TSIPV4ENA rw — Enable Processing of PTP Frames Sent over IPv4-UDP
  [12] TSIPV6ENA rw — Enable Processing of PTP Frames Sent Over IPv6-UDP
  [11] TSIPENA rw — Enable Processing of PTP over Ethernet Frames
  [10] TSVER2ENA rw — Enable PTP packet Processing for Version 2 Format
  [9] TSCTRLSSR rw — Timestamp Digital or Binary Rollover Control
  [8] TSENALL rw — Enable Timestamp for All Frames
  [5] TSADDREG rw — Addend Reg Update
  [4] TSTRIG rw — Timestamp Interrupt Trigger Enable
  [3] TSUPDT rw — Timestamp Update
  [2] TSINIT rw — Timestamp Initialize
  [1] TSCFUPDT rw — Timestamp Fine or Coarse Update
  [0] TSENA rw — Timestamp Enable
0x704 SUB_SECOND_INCREMENT access per field
  [7:0] SSINC rw — Sub-second Increment Value
0x708 SYSTEM_TIME_SECONDS ro
  [31:0] TSS — Timestamp Second
0x70C SYSTEM_TIME_NANOSECONDS ro
  [30:0] TSSS — Timestamp Sub Seconds
0x710 SYSTEM_TIME_SECONDS_UPDATE
  [31:0] TSS — Timestamp Second
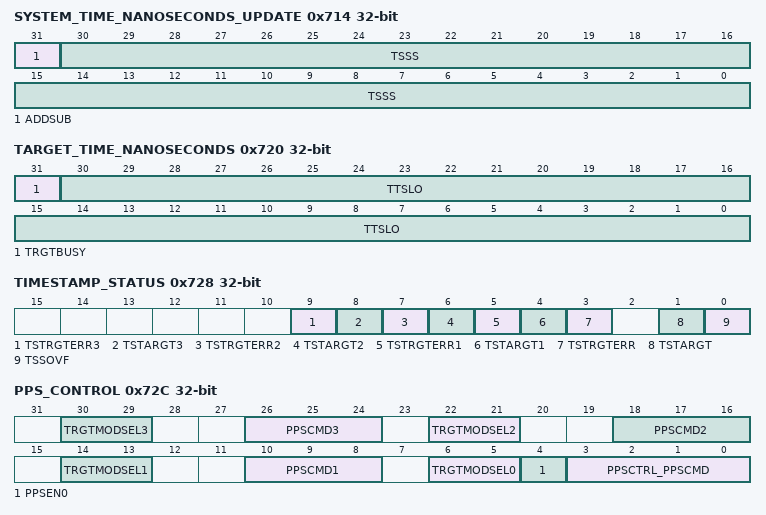
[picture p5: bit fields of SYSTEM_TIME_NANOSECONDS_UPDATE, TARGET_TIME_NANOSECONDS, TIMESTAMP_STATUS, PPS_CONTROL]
0x714 SYSTEM_TIME_NANOSECONDS_UPDATE
  [31] ADDSUB — Add or subtract time
  [30:0] TSSS — Timestamp Sub Second
0x718 TIMESTAMP_ADDEND
  [31:0] TSAR
0x71C TARGET_TIME_SECONDS
  [31:0] TSTR
0x720 TARGET_TIME_NANOSECONDS access per field
  [31] TRGTBUSY ro — Target Time Register Busy
  [30:0] TTSLO rw — Target Timestamp Low Register
0x724 SYSTEM_TIME_HIGHER_WORD_SECONDS access per field
  [15:0] TSHWR rw — Timestamp Higher Word Register
0x728 TIMESTAMP_STATUS ro
  [9] TSTRGTERR3 — Timestamp Target Time Error
  [8] TSTARGT3 — Timestamp Target Time Reached for Target Time PPS3
  [7] TSTRGTERR2 — Timestamp Target Time Error
  [6] TSTARGT2 — Timestamp Target Time Reached for Target Time PPS2
  [5] TSTRGTERR1 — Timestamp Target Time Error
  [4] TSTARGT1 — Timestamp Target Time Reached for Target Time PPS1
  [3] TSTRGTERR — Timestamp Target Time Error
  [1] TSTARGT — Timestamp Target Time Reached
  [0] TSSOVF — Timestamp Seconds Overflow
0x72C PPS_CONTROL access per field
  [8n+6:8n+5] TRGTMODSEL{n} ro (n=0..3) — Target Time Register Mode for PPS{n} Output
  [26:24] PPSCMD3 ro — Flexible PPS3 Output Control
  [18:16] PPSCMD2 ro — Flexible PPS2 Output Control
  [10:8] PPSCMD1 ro — Flexible PPS1 Output Control
  [4] PPSEN0 ro — Flexible PPS Output Mode Enable
  [3:0] PPSCTRL_PPSCMD rw — PPSCTRL0 or PPSCMD0
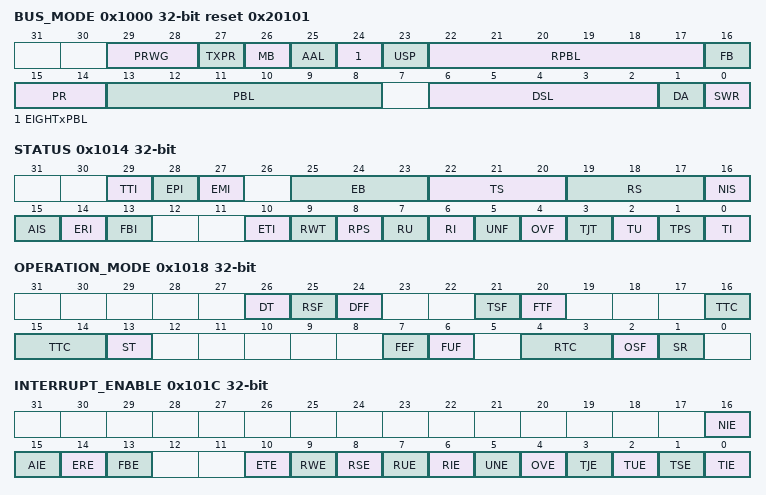
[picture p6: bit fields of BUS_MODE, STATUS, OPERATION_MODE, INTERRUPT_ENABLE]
0x1000 BUS_MODE access per field reset 0x20101
  [29:28] PRWG ro — Channel Priority Weights
  [27] TXPR rw — Transmit Priority
  [26] MB rw — Mixed Burst
  [25] AAL rw — Address Aligned Beats
  [24] EIGHTxPBL rw — 8xPBL Mode
  [23] USP rw — Use Seperate PBL
  [22:17] RPBL rw — Rx DMA PBL
  [16] FB rw — Fixed Burst
  [15:14] PR rw — Priority Ratio
  [13:8] PBL rw — Programmable Burst Length
  [6:2] DSL rw — Descriptor Skip Length
  [1] DA rw — DMA Arbitration Scheme
  [0] SWR rw — Software Reset
0x1004 TRANSMIT_POLL_DEMAND
  [31:0] TPD — Transmit Poll Demand
0x1008 RECEIVE_POLL_DEMAND
  [31:0] RPD — Receive Poll Demand
0x100C RECEIVE_DESCRIPTOR_LIST_ADDRESS access per field — Receive Descriptor Address Register
  [31:2] RDESLA_32bit rw — Start of Receive List
0x1010 TRANSMIT_DESCRIPTOR_LIST_ADDRESS access per field — Transmit descripter Address Register
  [31:2] TDESLA_32bit rw — Start of Transmit List
0x1014 STATUS access per field
  [29] TTI ro — Timestamp Trigger Interrupt
  [28] EPI ro — ETH PMT Interrupt
  [27] EMI ro — ETH MMC Interrupt
  [25:23] EB ro — Error Bits
  [22:20] TS ro — Transmit Process State
  [19:17] RS ro — Received Process State
  [16] NIS rw — Normal Interrupt Summary
  [15] AIS rw — Abnormal Interrupt Summary
  [14] ERI rw — Early Receive Interrupt
  [13] FBI rw — Fatal Bus Error Interrupt
  [10] ETI rw — Early Transmit Interrupt
  [9] RWT rw — Receive Watchdog Timeout
  [8] RPS rw — Receive Process Stopped
  [7] RU rw — Receive Buffer Unavailable
  [6] RI rw — Receive Interrupt
  [5] UNF rw — Transmit Underflow
  [4] OVF rw — Receive Overflow
  [3] TJT rw — Transmit Jabber Timeout
  [2] TU rw — Transmit Buffer Unavailable
  [1] TPS rw — Transmit Process Stopped
  [0] TI rw — Transmit Interrupt
0x1018 OPERATION_MODE access per field
  [26] DT rw — Disable Dropping of TCP/IP Checksum Error Frames
  [25] RSF rw — Receive Store and Forward
  [24] DFF rw — Disable Flushing of Received Frames
  [21] TSF rw — Transmit Store and Forward
  [20] FTF rw — Flush Transmit FIFO
  [16:14] TTC rw — Transmit Threshold Control
  [13] ST rw — Start or Stop Transmission Command
  [7] FEF rw — Forward Error Frames
  [6] FUF rw — Forward Undersized Good Frames
  [4:3] RTC rw — Receive Threshold Control
  [2] OSF rw — Operate on Second Frame
  [1] SR rw — Start or Stop Receive
0x101C INTERRUPT_ENABLE access per field
  [16] NIE rw — Normal Interrupt Summary Enable
  [15] AIE rw — Abnormal Interrupt Summary Enable
  [14] ERE rw — Early Receive Interrupt Enable
  [13] FBE rw — Fatal Bus Error Enable
  [10] ETE rw — Early Transmit Interrupt Enable
  [9] RWE rw — Receive Watchdog Timeout Enable
  [8] RSE rw — Receive Stopped Enable
  [7] RUE rw — Receive Buffer Unavailable Enable
  [6] RIE rw — Receive Interrupt Enable
  [5] UNE rw — Underflow Interrupt Enable
  [4] OVE rw — Overflow Interrupt Enable
  [3] TJE rw — Transmit Jabber Timeout Enable
  [2] TUE rw — Transmit Buffer Unvailable Enable
  [1] TSE rw — Transmit Stopped Enable
  [0] TIE rw — Transmit Interrupt Enable
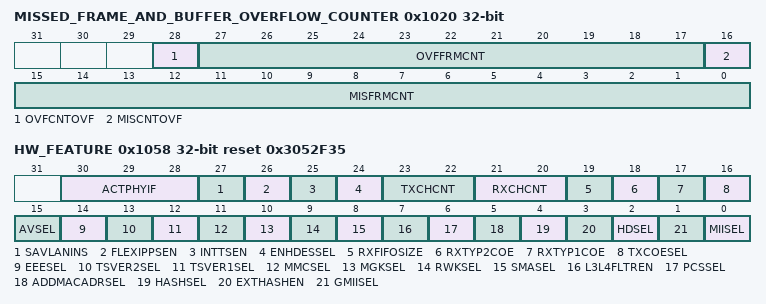
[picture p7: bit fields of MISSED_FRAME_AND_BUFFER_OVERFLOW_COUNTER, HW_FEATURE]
0x1020 MISSED_FRAME_AND_BUFFER_OVERFLOW_COUNTER ro
  [28] OVFCNTOVF — Overflow bit for FIFO Overflow Counter
  [27:17] OVFFRMCNT — This field indicates the number of frames missed by the application. The counter is cleared when this register is read.
  [16] MISCNTOVF — Overflow bit for Missed Frame Counter
  [15:0] MISFRMCNT — This field indicates the number of frames missed by the controller because of the RAM Receive Buffer being unavailable. This counter is incremented each time the DMA discards an incoming frame. The counter is cleared when this register is read.
0x1024 RECEIVE_INTERRUPT_WATCHDOG_TIMER access per field
  [7:0] RIWT rw — RI Watchdog Timer Count
0x102C AHB_STATUS ro
  [0] AHBMS — AHB Master Status
0x1048 CURRENT_HOST_TRANSMIT_DESCRIPTOR ro
  [31:0] CURTDESAPTR — Host Transmit Descriptor Address Pointer
0x104C CURRENT_HOST_RECEIVE_DESCRIPTOR ro
  [31:0] CURRDESAPTR — Host Receive Descriptor Address Pointer
0x1050 CURRENT_HOST_TRANSMIT_BUFFER_ADDRESS ro
  [31:0] CURTBUFAPTR — Host Transmit Buffer Address Pointer
0x1054 CURRENT_HOST_RECEIVE_BUFFER_ADDRESS ro
  [31:0] CURRBUFAPTR — Host Receive Buffer Address Pointer
0x1058 HW_FEATURE access per field reset 0x3052F35
  [30:28] ACTPHYIF ro — Active or Selected PHY interface
  [27] SAVLANINS ro — Source Address or VLAN Insertion
  [26] FLEXIPPSEN ro — Flexible Pulse-Per-Second Output
  [25] INTTSEN ro — Timestamping with Internal System Time
  [24] ENHDESSEL ro — Alternate (Enhanced Descriptor)
  [23:22] TXCHCNT ro — Number of additional Tx channels
  [21:20] RXCHCNT ro — Number of additional Rx channels
  [19] RXFIFOSIZE rw — Rx FIFO > 2,048 Bytes
  [18] RXTYP2COE ro — IP Checksum Offload (Type 2) in Rx
  [17] RXTYP1COE ro — IP Checksum Offload (Type 1) in Rx
  [16] TXCOESEL ro — Checksum Offload in Tx
  [15] AVSEL ro — AV Feature
  [14] EEESEL ro — Energy Efficient Ethernet
  [13] TSVER2SEL ro — IEEE 1588-2008 Advanced Timestamp
  [12] TSVER1SEL ro — Only IEEE 1588-2002 Timestamp
  [11] MMCSEL ro — RMON Module
  [10] MGKSEL ro — PMT Magic Packet
  [9] RWKSEL ro — PMT Remote Wakeup
  [8] SMASEL ro — SMA (MDIO) Interface
  [7] L3L4FLTREN ro — Layer 3 and Layer 4 Filter Feature
  [6] PCSSEL ro — PCS registers (TBI, SGMII, or RTBI PHY interface)
  [5] ADDMACADRSEL ro — Multiple MAC Address Registers
  [4] HASHSEL ro — HASH Filter
  [3] EXTHASHEN ro — Expanded DA Hash Filter
  [2] HDSEL ro — Half-Duplex support
  [1] GMIISEL ro — 1000 Mbps support
  [0] MIISEL ro — 10 or 100 Mbps support
